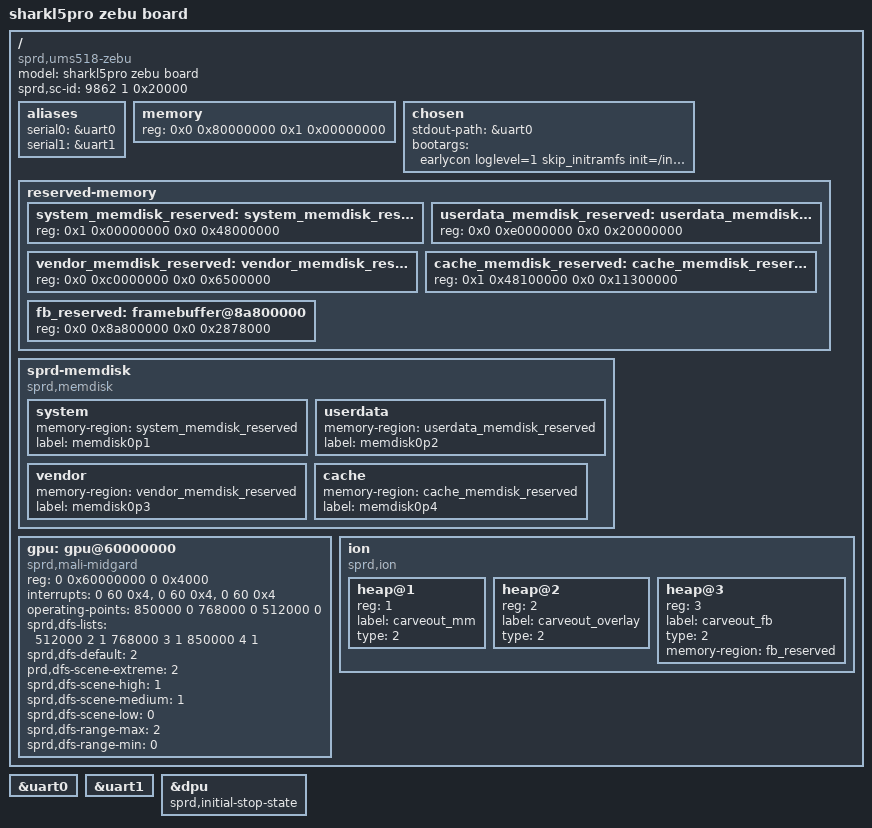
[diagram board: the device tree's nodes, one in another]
// SPDX-License-Identifier: (GPL-2.0+ OR MIT)
/*
 * Unisoc Sharkl5Pro platform DTS file
 *
 * Copyright (C) 2018, Unisoc Communications Inc.
 */

/dts-v1/;

#include "ums518-zebu.dtsi"
#include "ums518-zebu-mach.dtsi"

/ {
	model = "sharkl5pro zebu board";

	compatible = "sprd,ums518-zebu";

	sprd,sc-id = <9862 1 0x20000>;

	aliases {
		serial0 = &uart0;
		serial1 = &uart1;
	};

	memory {
		device_type = "memory";
		reg = <0x0 0x80000000 0x1 0x00000000>;
	};

	chosen {
		stdout-path = &uart0;
		bootargs = "earlycon loglevel=1 skip_initramfs init=/init root=/dev/memdisk0p1 rootfstype=ext4 ro rootwait androidboot.hardware=ums518_zebu androidboot.selinux=permissive printk.devkmsg=on";
	};

	reserved-memory {
		#address-cells = <2>;
		#size-cells = <2>;
		ranges;

		system_memdisk_reserved: system_memdisk_reserved@100000000{
			reg = <0x1 0x00000000 0x0 0x48000000>;  /* system 1536M */
		};

		userdata_memdisk_reserved: userdata_memdisk_reserved@e0000000{
			reg = <0x0 0xe0000000 0x0 0x20000000>; /* userdata 512M */
		};

		vendor_memdisk_reserved: vendor_memdisk_reserved@c0000000{
			reg = <0x0 0xc0000000 0x0 0x6500000>; /* vendor 100M */
		};

		cache_memdisk_reserved: cache_memdisk_reserved@148100000{
			reg = <0x1 0x48100000 0x0 0x11300000>; /* cache 275M */
		};

		fb_reserved: framebuffer@8a800000{
				reg = <0x0 0x8a800000 0x0 0x2878000>;
		};
	};

	sprd-memdisk {
		compatible = "sprd,memdisk";

		system {
			memory-region = <&system_memdisk_reserved>;
			label = "memdisk0p1";
		};

		userdata {
			memory-region = <&userdata_memdisk_reserved>;
			label = "memdisk0p2";
		};

		vendor {
			memory-region = <&vendor_memdisk_reserved>;
			label = "memdisk0p3";
		};

		cache {
			memory-region = <&cache_memdisk_reserved>;
			label = "memdisk0p4";
		};
	};

	gpu: gpu@60000000 {
		 compatible = "sprd,mali-midgard";
		 reg = <0 0x60000000 0 0x4000>;
		 interrupts = <0 60 0x4>,
			<0 60 0x4>,
			<0 60 0x4>;

		 interrupt-names = "JOB",
			 "MMU",
			 "GPU";

		 operating-points = <
			 // kHz    uV
			 850000    0
			 768000    0
			 512000    0
			 >;
		 sprd,dfs-lists = <
			 // kHz idx div
			 512000 2   1
			 768000 3   1
			 850000 4   1
			 >;

		 sprd,dfs-default = <2>;
		 prd,dfs-scene-extreme = <2>;
		 sprd,dfs-scene-high = <1>;
		 sprd,dfs-scene-medium = <1>;
		 sprd,dfs-scene-low = <0>;
		 sprd,dfs-range-max = <2>;
		 sprd,dfs-range-min = <0>;
	 };

	ion {
		compatible = "sprd,ion";
		#address-cells = <1>;
		#size-cells = <0>;

		heap@1 {
			reg = <1>;
			label = "carveout_mm";
			type = <2>;
		};

		heap@2 {
			reg = <2>;
			label = "carveout_overlay";
			type = <2>;
			/* memory-region = <&overlay_reserved>;*/
		};

		heap@3 {
			reg = <3>;
			label = "carveout_fb";
			type = <2>;
			memory-region = <&fb_reserved>;
		};
	};
};

&uart0 {
	status = "okay";
};

&uart1 {
	status = "okay";
};

&dpu {
	sprd,initial-stop-state;
	status = "okay";
};
